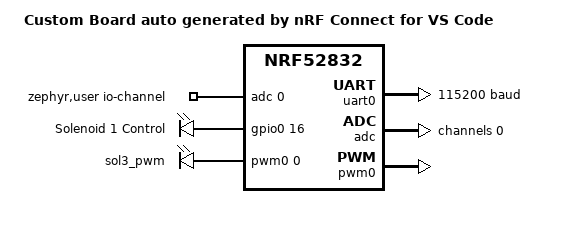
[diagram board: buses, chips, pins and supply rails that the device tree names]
/dts-v1/;
#include <nordic/nrf52832_qfaa.dtsi>
#include "nrf52832_felk_control_board-pinctrl.dtsi"

/ {
	model = "Custom Board auto generated by nRF Connect for VS Code";
	compatible = "Nordic_Semiconductor,nrf52832-felk-control-board";

	chosen {
		zephyr,console = &uart0;
		zephyr,uart-mcumgr = &uart0;
		zephyr,sram = &sram0;
		zephyr,flash = &flash0;
		zephyr,code-partition = &slot0_partition;
	};

	zephyr,user {
		io-channels = <&adc 0>;
	};

	solenoids {
		compatible = "gpio-leds";
		sol1: sol_1 {
			gpios = <&gpio0 16 GPIO_ACTIVE_HIGH>;
			label = "Solenoid 1 Control";
		};

	};

	aliases {
		sol1 = &sol1;
	};

	pwm_control {
		compatible = "pwm-leds";
		sol3_pwm: sol3_pwm {
			pwms = <&pwm0 0 PWM_MSEC(20) PWM_POLARITY_NORMAL>;
	
		};
	};


};


&flash0 {
	partitions {
		compatible = "fixed-partitions";
		#address-cells = <1>;
		#size-cells = <1>;

		boot_partition: partition@0 {
			label = "mcuboot";
			reg = <0x00000000 DT_SIZE_K(48)>;
		};

		slot0_partition: partition@c000 {
			label = "image-0";
			reg = <0x0000c000 DT_SIZE_K(200)>;
		};

		slot1_partition: partition@3e000 {
			label = "image-1";
			reg = <0x0003e000 DT_SIZE_K(200)>;
		};

		scratch_partition: partition@70000 {
			label = "image-scratch";
			reg = <0x70000 DT_SIZE_K(40)>;
		};

		storage_partition: partition@7a000 {
			label = "storage";
			reg = <0x0007a000 DT_SIZE_K(24)>;
		};
	};
};

&gpio0 {
	status = "okay";
};


&gpiote {
	status = "okay";
};

&uart0 {
	compatible = "nordic,nrf-uarte";
	status = "okay";
	current-speed = <115200>;
	pinctrl-0 = <&uart0_default>;
	pinctrl-1 = <&uart0_sleep>;
	pinctrl-names = "default", "sleep";

};

&adc {
	status = "okay";

	#address-cells = <1>;
	#size-cells = <0>;

	channel@0 {
		reg = <0>;
		zephyr,gain = "ADC_GAIN_1_6";
		zephyr,reference = "ADC_REF_INTERNAL";
		zephyr,acquisition-time = <ADC_ACQ_TIME_DEFAULT>;
		zephyr,input-positive = <NRF_SAADC_VDD>;
		zephyr,resolution = <14>;
		zephyr,oversampling = <8>;
	};
};

&pwm0 {
	status = "okay";
	pinctrl-0 = <&pwm0_default>;
	pinctrl-1 = <&pwm0_sleep>;
	pinctrl-names = "default", "sleep";
};
